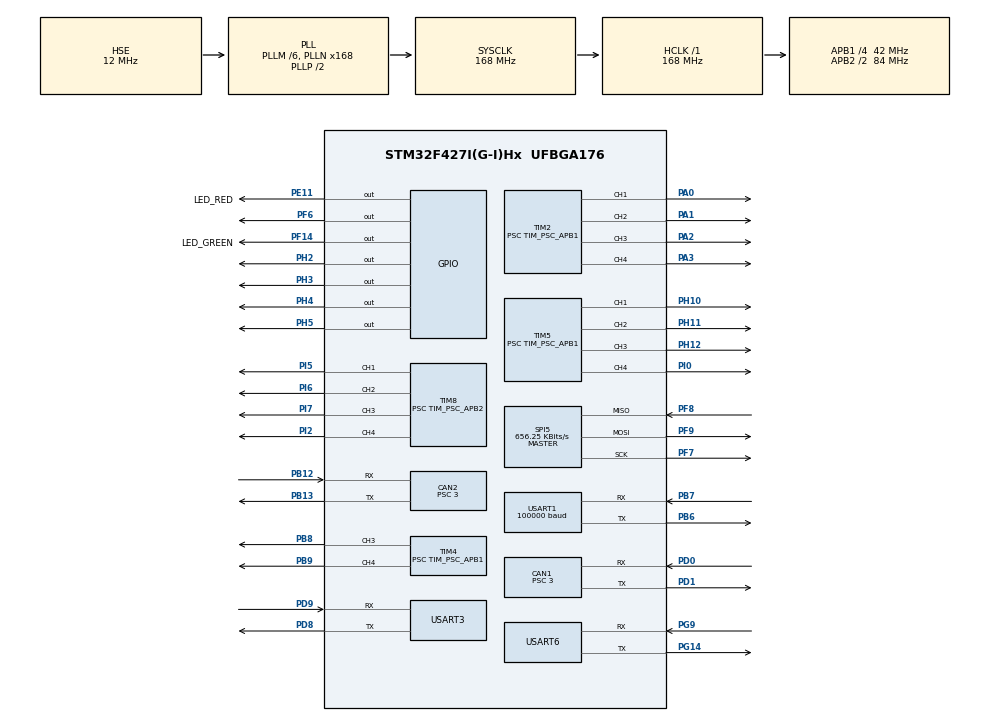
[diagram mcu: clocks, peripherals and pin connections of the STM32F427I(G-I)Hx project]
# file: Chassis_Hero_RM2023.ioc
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CAN1.BS1=CAN_BS1_10TQ
CAN1.BS2=CAN_BS2_3TQ
CAN1.CalculateBaudRate=1000000
CAN1.CalculateTimeBit=1000
CAN1.CalculateTimeQuantum=71.42857142857143
CAN1.NART=ENABLE
CAN1.Prescaler=3
CAN1.SJW=CAN_SJW_2TQ
CAN2.BS1=CAN_BS1_10TQ
CAN2.BS2=CAN_BS2_3TQ
CAN2.CalculateBaudRate=1000000
CAN2.CalculateTimeBit=1000
CAN2.CalculateTimeQuantum=71.42857142857143
CAN2.NART=ENABLE
CAN2.Prescaler=3
CAN2.SJW=CAN_SJW_2TQ
Dma.Request0=USART1_RX
Dma.Request1=USART3_TX
Dma.Request2=USART3_RX
Dma.Request3=USART6_RX
Dma.Request4=USART6_TX
Dma.USART1_RX.0.Direction=DMA_PERIPH_TO_MEMORY
Dma.USART1_RX.0.FIFOMode=DMA_FIFOMODE_DISABLE
Dma.USART1_RX.0.Instance=DMA2_Stream2
Dma.USART1_RX.0.MemDataAlignment=DMA_MDATAALIGN_BYTE
Dma.USART1_RX.0.MemInc=DMA_MINC_ENABLE
Dma.USART1_RX.0.Mode=DMA_CIRCULAR
Dma.USART1_RX.0.PeriphDataAlignment=DMA_PDATAALIGN_BYTE
Dma.USART1_RX.0.PeriphInc=DMA_PINC_DISABLE
Dma.USART1_RX.0.Priority=DMA_PRIORITY_LOW
Dma.USART3_RX.2.Direction=DMA_PERIPH_TO_MEMORY
Dma.USART3_RX.2.FIFOMode=DMA_FIFOMODE_DISABLE
Dma.USART3_RX.2.Instance=DMA1_Stream1
Dma.USART3_RX.2.MemDataAlignment=DMA_MDATAALIGN_BYTE
Dma.USART3_RX.2.MemInc=DMA_MINC_ENABLE
Dma.USART3_RX.2.Mode=DMA_NORMAL
Dma.USART3_RX.2.PeriphDataAlignment=DMA_PDATAALIGN_BYTE
Dma.USART3_RX.2.PeriphInc=DMA_PINC_DISABLE
Dma.USART3_RX.2.Priority=DMA_PRIORITY_VERY_HIGH
Dma.USART3_TX.1.Direction=DMA_MEMORY_TO_PERIPH
Dma.USART3_TX.1.FIFOMode=DMA_FIFOMODE_DISABLE
Dma.USART3_TX.1.Instance=DMA1_Stream4
Dma.USART3_TX.1.MemDataAlignment=DMA_MDATAALIGN_BYTE
Dma.USART3_TX.1.MemInc=DMA_MINC_ENABLE
Dma.USART3_TX.1.Mode=DMA_NORMAL
Dma.USART3_TX.1.PeriphDataAlignment=DMA_PDATAALIGN_BYTE
Dma.USART3_TX.1.PeriphInc=DMA_PINC_DISABLE
Dma.USART3_TX.1.Priority=DMA_PRIORITY_HIGH
Dma.USART6_RX.3.Direction=DMA_PERIPH_TO_MEMORY
Dma.USART6_RX.3.FIFOMode=DMA_FIFOMODE_DISABLE
Dma.USART6_RX.3.Instance=DMA2_Stream1
Dma.USART6_RX.3.MemDataAlignment=DMA_MDATAALIGN_BYTE
Dma.USART6_RX.3.MemInc=DMA_MINC_ENABLE
Dma.USART6_RX.3.Mode=DMA_NORMAL
Dma.USART6_RX.3.PeriphDataAlignment=DMA_PDATAALIGN_BYTE
Dma.USART6_RX.3.PeriphInc=DMA_PINC_DISABLE
Dma.USART6_RX.3.Priority=DMA_PRIORITY_HIGH
Dma.USART6_TX.4.Direction=DMA_MEMORY_TO_PERIPH
Dma.USART6_TX.4.FIFOMode=DMA_FIFOMODE_DISABLE
Dma.USART6_TX.4.Instance=DMA2_Stream6
Dma.USART6_TX.4.MemDataAlignment=DMA_MDATAALIGN_BYTE
Dma.USART6_TX.4.MemInc=DMA_MINC_ENABLE
Dma.USART6_TX.4.Mode=DMA_NORMAL
Dma.USART6_TX.4.PeriphDataAlignment=DMA_PDATAALIGN_BYTE
Dma.USART6_TX.4.PeriphInc=DMA_PINC_DISABLE
Dma.USART6_TX.4.Priority=DMA_PRIORITY_VERY_HIGH
FREERTOS.INCLUDE_eTaskGetState=1
FREERTOS.INCLUDE_pcTaskGetTaskName=1
FREERTOS.INCLUDE_uxTaskGetStackHighWaterMark=1
FREERTOS.INCLUDE_vTaskCleanUpResources=1
FREERTOS.INCLUDE_vTaskDelayUntil=1
FREERTOS.INCLUDE_xEventGroupSetBitFromISR=1
FREERTOS.INCLUDE_xQueueGetMutexHolder=1
FREERTOS.INCLUDE_xSemaphoreGetMutexHolder=1
FREERTOS.INCLUDE_xTaskAbortDelay=1
FREERTOS.INCLUDE_xTaskGetCurrentTaskHandle=1
FREERTOS.INCLUDE_xTaskGetHandle=1
FREERTOS.INCLUDE_xTimerPendFunctionCall=1
FREERTOS.Tasks01=Chassis_Task,0,512,chassis_task,As weak,NULL,Dynamic,NULL,NULL;Referee_Task,0,512,referee_task,As weak,NULL,Dynamic,NULL,NULL;Comm_Task,0,512,comm_task,As weak,NULL,Dynamic,NULL,NULL;Referee_Unpack,0,480,Referee_Usart_Unpack,As weak,NULL,Dynamic,NULL,NULL
FREERTOS.configUSE_TIMERS=1
Mcu.Family=STM32F4
Mcu.Name=STM32F427I(G-I)Hx
Mcu.Package=UFBGA176
Mcu.UserConstants=APB2_TIMER_CLOCKS,168000000;PWM_FREQUENCE,50;PWM_DEFAULT_DUTY,5000;TIM_PSC_APB1,((APB1_TIMER_CLOCKS/PWM_FREQUENCE)/PWM_RESOLUTION -1);PWM_RESOLUTION,10000;TIM_PSC_APB2,((APB2_TIMER_CLOCKS/PWM_FREQUENCE)/PWM_RESOLUTION -1);APB1_TIMER_CLOCKS,84000000
NVIC.CAN1_RX0_IRQn=true\:5\:0\:false\:false\:true\:true\:true\:true\:true
NVIC.CAN1_RX1_IRQn=true\:5\:0\:false\:false\:true\:true\:true\:true\:true
NVIC.CAN2_RX0_IRQn=true\:5\:0\:false\:false\:true\:true\:true\:true\:true
NVIC.CAN2_RX1_IRQn=true\:5\:0\:false\:false\:true\:true\:true\:true\:true
NVIC.DMA1_Stream1_IRQn=true\:5\:0\:false\:false\:true\:true\:false\:true\:true
NVIC.DMA1_Stream4_IRQn=true\:5\:0\:false\:false\:true\:false\:false\:true\:true
NVIC.DMA2_Stream1_IRQn=true\:5\:0\:false\:false\:true\:true\:false\:true\:true
NVIC.DMA2_Stream2_IRQn=true\:5\:0\:false\:false\:true\:true\:false\:true\:true
NVIC.DMA2_Stream6_IRQn=true\:5\:0\:false\:false\:true\:true\:false\:true\:true
NVIC.PriorityGroup=NVIC_PRIORITYGROUP_4
NVIC.USART1_IRQn=true\:5\:0\:false\:false\:false\:true\:true\:true\:true
NVIC.USART3_IRQn=true\:5\:0\:false\:false\:false\:true\:true\:true\:true
NVIC.USART6_IRQn=true\:5\:0\:false\:false\:true\:true\:true\:true\:true
PA0/WKUP.Signal=S_TIM2_CH1_ETR
PA1.Signal=S_TIM2_CH2
PA13.Mode=Serial_Wire
PA13.Signal=SYS_JTMS-SWDIO
PA14.Mode=Serial_Wire
PA14.Signal=SYS_JTCK-SWCLK
PA2.Signal=S_TIM2_CH3
PA3.Signal=S_TIM2_CH4
PB12.Mode=CAN_Activate
PB12.Signal=CAN2_RX
PB13.Mode=CAN_Activate
PB13.Signal=CAN2_TX
PB6.Mode=Asynchronous
PB6.Signal=USART1_TX
PB7.Mode=Asynchronous
PB7.Signal=USART1_RX
PB8.Signal=S_TIM4_CH3
PB9.Signal=S_TIM4_CH4
PD0.Mode=CAN_Activate
PD0.Signal=CAN1_RX
PD1.Mode=CAN_Activate
PD1.Signal=CAN1_TX
PD8.Mode=Asynchronous
PD8.Signal=USART3_TX
PD9.Mode=Asynchronous
PD9.Signal=USART3_RX
PE11.GPIO_Label=LED_RED
PE11.Signal=GPIO_Output
PF14.GPIO_Label=LED_GREEN
PF14.Signal=GPIO_Output
PF6.Signal=GPIO_Output
PF7.Mode=Full_Duplex_Master
PF7.Signal=SPI5_SCK
PF8.Mode=Full_Duplex_Master
PF8.Signal=SPI5_MISO
PF9.Mode=Full_Duplex_Master
PF9.Signal=SPI5_MOSI
PG14.Mode=Asynchronous
PG14.Signal=USART6_TX
PG9.Mode=Asynchronous
PG9.Signal=USART6_RX
PH0/OSC_IN.Mode=HSE-External-Oscillator
PH0/OSC_IN.Signal=RCC_OSC_IN
PH1/OSC_OUT.Mode=HSE-External-Oscillator
PH1/OSC_OUT.Signal=RCC_OSC_OUT
PH10.Signal=S_TIM5_CH1
PH11.Signal=S_TIM5_CH2
PH12.Signal=S_TIM5_CH3
PH2.Signal=GPIO_Output
PH3.Signal=GPIO_Output
PH4.Signal=GPIO_Output
PH5.Signal=GPIO_Output
PI0.Signal=S_TIM5_CH4
PI2.Signal=S_TIM8_CH4
PI5.Signal=S_TIM8_CH1
PI6.Signal=S_TIM8_CH2
PI7.Signal=S_TIM8_CH3
ProjectManager.HeapSize=0x200
ProjectManager.StackSize=0x400
ProjectManager.TargetToolchain=MDK-ARM V5
RCC.48MHZClocksFreq_Value=84000000
RCC.AHBFreq_Value=168000000
RCC.APB1CLKDivider=RCC_HCLK_DIV4
RCC.APB1Freq_Value=42000000
RCC.APB1TimFreq_Value=84000000
RCC.APB2CLKDivider=RCC_HCLK_DIV2
RCC.APB2Freq_Value=84000000
RCC.APB2TimFreq_Value=168000000
RCC.CortexFreq_Value=168000000
RCC.HCLKFreq_Value=168000000
RCC.HSE_VALUE=12000000
RCC.HSI_VALUE=16000000
RCC.LSE_VALUE=32768
RCC.PLLM=6
RCC.PLLN=168
RCC.PLLSourceVirtual=RCC_PLLSOURCE_HSE
RCC.SYSCLKFreq_VALUE=168000000
RCC.SYSCLKSource=RCC_SYSCLKSOURCE_PLLCLK
RCC.VCOOutputFreq_Value=336000000
SH.S_TIM2_CH1_ETR.0=TIM2_CH1,PWM Generation1 CH1
SH.S_TIM2_CH2.0=TIM2_CH2,PWM Generation2 CH2
SH.S_TIM2_CH3.0=TIM2_CH3,PWM Generation3 CH3
SH.S_TIM2_CH4.0=TIM2_CH4,PWM Generation4 CH4
SH.S_TIM4_CH3.0=TIM4_CH3,PWM Generation3 CH3
SH.S_TIM4_CH4.0=TIM4_CH4,PWM Generation4 CH4
SH.S_TIM5_CH1.0=TIM5_CH1,PWM Generation1 CH1
SH.S_TIM5_CH2.0=TIM5_CH2,PWM Generation2 CH2
SH.S_TIM5_CH3.0=TIM5_CH3,PWM Generation3 CH3
SH.S_TIM5_CH4.0=TIM5_CH4,PWM Generation4 CH4
SH.S_TIM8_CH1.0=TIM8_CH1,PWM Generation1 CH1
SH.S_TIM8_CH2.0=TIM8_CH2,PWM Generation2 CH2
SH.S_TIM8_CH3.0=TIM8_CH3,PWM Generation3 CH3
SH.S_TIM8_CH4.0=TIM8_CH4,PWM Generation4 CH4
SPI5.BaudRatePrescaler=SPI_BAUDRATEPRESCALER_128
SPI5.CalculateBaudRate=656.25 KBits/s
SPI5.Direction=SPI_DIRECTION_2LINES
SPI5.Mode=SPI_MODE_MASTER
SPI5.VirtualType=VM_MASTER
TIM2.Channel-PWM\ Generation1\ CH1=TIM_CHANNEL_1
TIM2.Channel-PWM\ Generation2\ CH2=TIM_CHANNEL_2
TIM2.Channel-PWM\ Generation3\ CH3=TIM_CHANNEL_3
TIM2.Channel-PWM\ Generation4\ CH4=TIM_CHANNEL_4
TIM2.Period=PWM_RESOLUTION-1
TIM2.Prescaler=TIM_PSC_APB1
TIM2.Pulse-PWM\ Generation1\ CH1=PWM_DEFAULT_DUTY
TIM2.Pulse-PWM\ Generation2\ CH2=PWM_DEFAULT_DUTY
TIM2.Pulse-PWM\ Generation3\ CH3=PWM_DEFAULT_DUTY
TIM2.Pulse-PWM\ Generation4\ CH4=PWM_DEFAULT_DUTY
TIM4.Channel-PWM\ Generation1\ CH1=TIM_CHANNEL_1
TIM4.Channel-PWM\ Generation2\ CH2=TIM_CHANNEL_2
TIM4.Channel-PWM\ Generation3\ CH3=TIM_CHANNEL_3
TIM4.Channel-PWM\ Generation4\ CH4=TIM_CHANNEL_4
TIM4.Period=PWM_RESOLUTION-1
TIM4.Prescaler=TIM_PSC_APB1
TIM4.Pulse-PWM\ Generation1\ CH1=PWM_DEFAULT_DUTY
TIM4.Pulse-PWM\ Generation2\ CH2=PWM_DEFAULT_DUTY
TIM4.Pulse-PWM\ Generation3\ CH3=PWM_DEFAULT_DUTY
TIM4.Pulse-PWM\ Generation4\ CH4=PWM_DEFAULT_DUTY
TIM5.Channel-PWM\ Generation1\ CH1=TIM_CHANNEL_1
TIM5.Channel-PWM\ Generation2\ CH2=TIM_CHANNEL_2
TIM5.Channel-PWM\ Generation3\ CH3=TIM_CHANNEL_3
TIM5.Channel-PWM\ Generation4\ CH4=TIM_CHANNEL_4
TIM5.Period=PWM_RESOLUTION-1
TIM5.Prescaler=TIM_PSC_APB1
TIM5.Pulse-PWM\ Generation1\ CH1=PWM_DEFAULT_DUTY
TIM5.Pulse-PWM\ Generation2\ CH2=PWM_DEFAULT_DUTY
TIM5.Pulse-PWM\ Generation3\ CH3=PWM_DEFAULT_DUTY
TIM5.Pulse-PWM\ Generation4\ CH4=PWM_DEFAULT_DUTY
TIM8.Channel-PWM\ Generation1\ CH1=TIM_CHANNEL_1
TIM8.Channel-PWM\ Generation2\ CH2=TIM_CHANNEL_2
TIM8.Channel-PWM\ Generation3\ CH3=TIM_CHANNEL_3
TIM8.Channel-PWM\ Generation4\ CH4=TIM_CHANNEL_4
TIM8.Period=PWM_RESOLUTION-1
TIM8.Prescaler=TIM_PSC_APB2
TIM8.Pulse-PWM\ Generation1\ CH1=PWM_DEFAULT_DUTY
TIM8.Pulse-PWM\ Generation2\ CH2=PWM_DEFAULT_DUTY
TIM8.Pulse-PWM\ Generation3\ CH3=PWM_DEFAULT_DUTY
TIM8.Pulse-PWM\ Generation4\ CH4=PWM_DEFAULT_DUTY
USART1.BaudRate=100000
USART1.VirtualMode=VM_ASYNC
USART3.VirtualMode=VM_ASYNC
USART6.VirtualMode=VM_ASYNC
VP_CRC_VS_CRC.Mode=CRC_Activate
VP_FREERTOS_VS_CMSIS_V1.Mode=CMSIS_V1
board=custom

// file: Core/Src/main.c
/* USER CODE BEGIN Header */
/**
  ******************************************************************************
  * @file           : main.c
  * @brief          : Main program body
  ******************************************************************************
  * @attention
  *
  * Copyright (c) 2023 STMicroelectronics.
  * All rights reserved.
  *
  * This software is licensed under terms that can be found in the LICENSE file
  * in the root directory of this software component.
  * If no LICENSE file comes with this software, it is provided AS-IS.
  *
  ******************************************************************************
  */
/* USER CODE END Header */
#include "main.h"
#include "cmsis_os.h"
#include "can.h"
#include "crc.h"
#include "dma.h"
#include "spi.h"
#include "tim.h"
#include "usart.h"
#include "gpio.h"

/* USER CODE BEGIN Includes */
#include "bsp_imu.h"
#include "bsp_can.h"
/* USER CODE END Includes */

void SystemClock_Config(void);
void MX_FREERTOS_Init(void);

int main(void)
{

  /* MCU Configuration--------------------------------------------------------*/

  /* Reset of all peripherals, Initializes the Flash interface and the Systick. */
  HAL_Init();

  /* Configure the system clock */
  SystemClock_Config();

  /* Initialize all configured peripherals */
  MX_GPIO_Init();
  MX_DMA_Init();
  MX_SPI5_Init();
  MX_USART6_UART_Init();
  MX_TIM2_Init();
  MX_TIM4_Init();
  MX_TIM5_Init();
  MX_TIM8_Init();
  MX_USART1_UART_Init();
  MX_CAN1_Init();
  MX_CAN2_Init();
  MX_USART3_UART_Init();
  MX_CRC_Init();
  /* USER CODE BEGIN 2 */
	can_filter_init();

	HAL_GPIO_WritePin(GPIOH, GPIO_PIN_2|GPIO_PIN_3|GPIO_PIN_4|GPIO_PIN_5, GPIO_PIN_SET);//开启A板四个可控电源输出

//	dbus_uart_init();//遥控器初始化
  /* USER CODE END 2 */

  /* Call init function for freertos objects (in freertos.c) */
  MX_FREERTOS_Init();

  /* Start scheduler */
  osKernelStart();
  /* We should never get here as control is now taken by the scheduler */
  /* Infinite loop */
  while (1)
  {

  }
}

void SystemClock_Config(void)
{
  RCC_OscInitTypeDef RCC_OscInitStruct = {0};
  RCC_ClkInitTypeDef RCC_ClkInitStruct = {0};

  /** Configure the main internal regulator output voltage
  */
  __HAL_RCC_PWR_CLK_ENABLE();
  __HAL_PWR_VOLTAGESCALING_CONFIG(PWR_REGULATOR_VOLTAGE_SCALE1);

  /** Initializes the RCC Oscillators according to the specified parameters
  * in the RCC_OscInitTypeDef structure.
  */
  RCC_OscInitStruct.OscillatorType = RCC_OSCILLATORTYPE_HSE;
  RCC_OscInitStruct.HSEState = RCC_HSE_ON;
  RCC_OscInitStruct.PLL.PLLState = RCC_PLL_ON;
  RCC_OscInitStruct.PLL.PLLSource = RCC_PLLSOURCE_HSE;
  RCC_OscInitStruct.PLL.PLLM = 6;
  RCC_OscInitStruct.PLL.PLLN = 168;
  RCC_OscInitStruct.PLL.PLLP = RCC_PLLP_DIV2;
  RCC_OscInitStruct.PLL.PLLQ = 4;
  if (HAL_RCC_OscConfig(&RCC_OscInitStruct) != HAL_OK)
  {
    Error_Handler();
  }

  /** Initializes the CPU, AHB and APB buses clocks
  */
  RCC_ClkInitStruct.ClockType = RCC_CLOCKTYPE_HCLK|RCC_CLOCKTYPE_SYSCLK
                              |RCC_CLOCKTYPE_PCLK1|RCC_CLOCKTYPE_PCLK2;
  RCC_ClkInitStruct.SYSCLKSource = RCC_SYSCLKSOURCE_PLLCLK;
  RCC_ClkInitStruct.AHBCLKDivider = RCC_SYSCLK_DIV1;
  RCC_ClkInitStruct.APB1CLKDivider = RCC_HCLK_DIV4;
  RCC_ClkInitStruct.APB2CLKDivider = RCC_HCLK_DIV2;

  if (HAL_RCC_ClockConfig(&RCC_ClkInitStruct, FLASH_LATENCY_5) != HAL_OK)
  {
    Error_Handler();
  }
}

void Error_Handler(void)
{
  __disable_irq();
  while (1)
  {
  }
}

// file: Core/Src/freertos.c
/* USER CODE BEGIN Header */
/**
  ******************************************************************************
  * File Name          : freertos.c
  * Description        : Code for freertos applications
  ******************************************************************************
  * @attention
  *
  * Copyright (c) 2023 STMicroelectronics.
  * All rights reserved.
  *
  * This software is licensed under terms that can be found in the LICENSE file
  * in the root directory of this software component.
  * If no LICENSE file comes with this software, it is provided AS-IS.
  *
  ******************************************************************************
  */
/* USER CODE END Header */

#include "FreeRTOS.h"
#include "task.h"
#include "main.h"
#include "cmsis_os.h"

osThreadId Chassis_TaskHandle;
osThreadId Referee_TaskHandle;
osThreadId Comm_TaskHandle;
osThreadId Referee_UnpackHandle;

void chassis_task(void const * argument);
void referee_task(void const * argument);
void comm_task(void const * argument);
void Referee_Usart_Unpack(void const * argument);

void MX_FREERTOS_Init(void); /* (MISRA C 2004 rule 8.1) */

/* GetIdleTaskMemory prototype (linked to static allocation support) */
void vApplicationGetIdleTaskMemory( StaticTask_t **ppxIdleTaskTCBBuffer, StackType_t **ppxIdleTaskStackBuffer, uint32_t *pulIdleTaskStackSize );

/* GetTimerTaskMemory prototype (linked to static allocation support) */
void vApplicationGetTimerTaskMemory( StaticTask_t **ppxTimerTaskTCBBuffer, StackType_t **ppxTimerTaskStackBuffer, uint32_t *pulTimerTaskStackSize );

/* USER CODE BEGIN GET_IDLE_TASK_MEMORY */
static StaticTask_t xIdleTaskTCBBuffer;
static StackType_t xIdleStack[configMINIMAL_STACK_SIZE];

void vApplicationGetIdleTaskMemory( StaticTask_t **ppxIdleTaskTCBBuffer, StackType_t **ppxIdleTaskStackBuffer, uint32_t *pulIdleTaskStackSize )
{
  *ppxIdleTaskTCBBuffer = &xIdleTaskTCBBuffer;
  *ppxIdleTaskStackBuffer = &xIdleStack[0];
  *pulIdleTaskStackSize = configMINIMAL_STACK_SIZE;
  /* place for user code */
}
/* USER CODE END GET_IDLE_TASK_MEMORY */

/* USER CODE BEGIN GET_TIMER_TASK_MEMORY */
static StaticTask_t xTimerTaskTCBBuffer;
static StackType_t xTimerStack[configTIMER_TASK_STACK_DEPTH];

void vApplicationGetTimerTaskMemory( StaticTask_t **ppxTimerTaskTCBBuffer, StackType_t **ppxTimerTaskStackBuffer, uint32_t *pulTimerTaskStackSize )
{
  *ppxTimerTaskTCBBuffer = &xTimerTaskTCBBuffer;
  *ppxTimerTaskStackBuffer = &xTimerStack[0];
  *pulTimerTaskStackSize = configTIMER_TASK_STACK_DEPTH;
  /* place for user code */
}
/* USER CODE END GET_TIMER_TASK_MEMORY */

void MX_FREERTOS_Init(void) {

  /* Create the thread(s) */
  /* definition and creation of Chassis_Task */
  osThreadDef(Chassis_Task, chassis_task, osPriorityNormal, 0, 512);
  Chassis_TaskHandle = osThreadCreate(osThread(Chassis_Task), NULL);

  /* definition and creation of Referee_Task */
  osThreadDef(Referee_Task, referee_task, osPriorityNormal, 0, 512);
  Referee_TaskHandle = osThreadCreate(osThread(Referee_Task), NULL);

  /* definition and creation of Comm_Task */
  osThreadDef(Comm_Task, comm_task, osPriorityNormal, 0, 512);
  Comm_TaskHandle = osThreadCreate(osThread(Comm_Task), NULL);

  /* definition and creation of Referee_Unpack */
  osThreadDef(Referee_Unpack, Referee_Usart_Unpack, osPriorityNormal, 0, 480);
  Referee_UnpackHandle = osThreadCreate(osThread(Referee_Unpack), NULL);

}

__weak void chassis_task(void const * argument)
{
  for(;;)
  {
    osDelay(1);
  }
}

__weak void referee_task(void const * argument)
{
  for(;;)
  {
    osDelay(1);
  }
}

__weak void comm_task(void const * argument)
{
  for(;;)
  {
    osDelay(1);
  }
}

__weak void Referee_Usart_Unpack(void const * argument)
{
  for(;;)
  {
    osDelay(1);
  }
}
